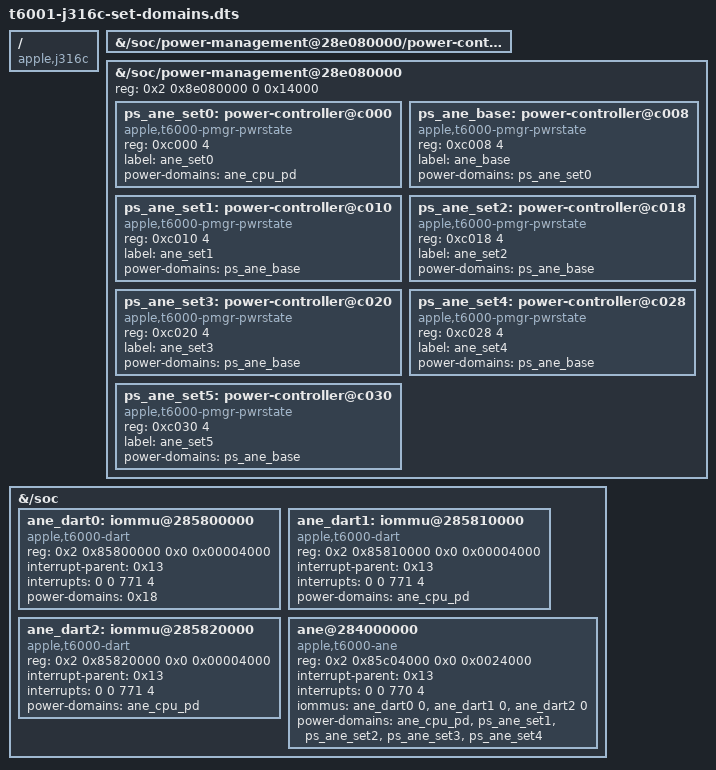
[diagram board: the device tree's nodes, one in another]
// SPDX-License-Identifier: GPL-2.0+ OR MIT
/*
 * Live overlay for t6001-test-host (J316c / T6001): grow die0 PMGR so SET0 at
 * 0x28e08c000 is inside the syscon, add T8103-shaped SET genpd, and
 * attach set1..5 plus the existing ps_ane_sys_cpu on the bound ANE node.
 *
 * Applied to the stock modules DTB. Do not write 0xf from userspace.
 */
/dts-v1/;
/plugin/;

/ {
	compatible = "apple,j316c", "apple,t6001";

	fragment@0 {
		target-path = "/soc/power-management@28e080000/power-controller@2c8";

		ane_cpu_pd: __overlay__ {
		};
	};

	fragment@1 {
		target-path = "/soc/power-management@28e080000";

		__overlay__ {
			reg = <0x2 0x8e080000 0 0x14000>;

			ps_ane_set0: power-controller@c000 {
				compatible = "apple,t6000-pmgr-pwrstate", "apple,pmgr-pwrstate";
				reg = <0xc000 4>;
				#power-domain-cells = <0>;
				#reset-cells = <0>;
				label = "ane_set0";
				power-domains = <&ane_cpu_pd>;
			};

			ps_ane_base: power-controller@c008 {
				compatible = "apple,t6000-pmgr-pwrstate", "apple,pmgr-pwrstate";
				reg = <0xc008 4>;
				#power-domain-cells = <0>;
				#reset-cells = <0>;
				label = "ane_base";
				power-domains = <&ps_ane_set0>;
			};

			ps_ane_set1: power-controller@c010 {
				compatible = "apple,t6000-pmgr-pwrstate", "apple,pmgr-pwrstate";
				reg = <0xc010 4>;
				#power-domain-cells = <0>;
				#reset-cells = <0>;
				label = "ane_set1";
				power-domains = <&ps_ane_base>;
			};

			ps_ane_set2: power-controller@c018 {
				compatible = "apple,t6000-pmgr-pwrstate", "apple,pmgr-pwrstate";
				reg = <0xc018 4>;
				#power-domain-cells = <0>;
				#reset-cells = <0>;
				label = "ane_set2";
				power-domains = <&ps_ane_base>;
			};

			ps_ane_set3: power-controller@c020 {
				compatible = "apple,t6000-pmgr-pwrstate", "apple,pmgr-pwrstate";
				reg = <0xc020 4>;
				#power-domain-cells = <0>;
				#reset-cells = <0>;
				label = "ane_set3";
				power-domains = <&ps_ane_base>;
			};

			ps_ane_set4: power-controller@c028 {
				compatible = "apple,t6000-pmgr-pwrstate", "apple,pmgr-pwrstate";
				reg = <0xc028 4>;
				#power-domain-cells = <0>;
				#reset-cells = <0>;
				label = "ane_set4";
				power-domains = <&ps_ane_base>;
			};

			ps_ane_set5: power-controller@c030 {
				compatible = "apple,t6000-pmgr-pwrstate", "apple,pmgr-pwrstate";
				reg = <0xc030 4>;
				#power-domain-cells = <0>;
				#reset-cells = <0>;
				label = "ane_set5";
				power-domains = <&ps_ane_base>;
			};
		};
	};

	fragment@2 {
		target-path = "/soc";

		__overlay__ {
			#address-cells = <2>;
			#size-cells = <2>;

			ane_dart0: iommu@285800000 {
				compatible = "apple,t6000-dart";
				reg = <0x2 0x85800000 0x0 0x00004000>;
				#iommu-cells = <1>;
				interrupt-parent = <0x13>;
				interrupts = <0 0 771 4>;
				power-domains = <0x18>;
				status = "okay";
			};

			ane_dart1: iommu@285810000 {
				compatible = "apple,t6000-dart";
				reg = <0x2 0x85810000 0x0 0x00004000>;
				#iommu-cells = <1>;
				interrupt-parent = <0x13>;
				interrupts = <0 0 771 4>;
				power-domains = <&ane_cpu_pd>;
				status = "okay";
			};

			ane_dart2: iommu@285820000 {
				compatible = "apple,t6000-dart";
				reg = <0x2 0x85820000 0x0 0x00004000>;
				#iommu-cells = <1>;
				interrupt-parent = <0x13>;
				interrupts = <0 0 771 4>;
				power-domains = <&ane_cpu_pd>;
				status = "okay";
			};

			ane@284000000 {
				compatible = "apple,t6000-ane";
				reg-names = "engine";
				reg = <0x2 0x85c04000 0x0 0x0024000>;
				interrupt-parent = <0x13>;
				interrupt-names = "ane";
				interrupts = <0 0 770 4>;
				iommus = <&ane_dart0 0>, <&ane_dart1 0>, <&ane_dart2 0>;
				/* set5@c030 is past ADT range1 0xc02c; genpd timed out. */
				power-domains = <&ane_cpu_pd>,
						<&ps_ane_set1>,
						<&ps_ane_set2>,
						<&ps_ane_set3>,
						<&ps_ane_set4>;
				status = "okay";
			};
		};
	};
};
